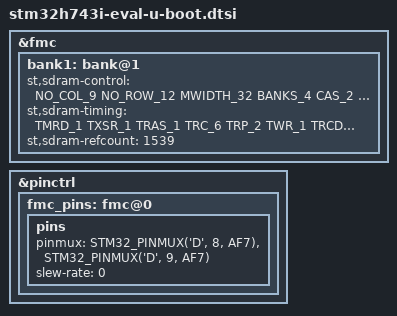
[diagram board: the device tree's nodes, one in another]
// SPDX-License-Identifier: GPL-2.0+

#include <stm32h7-u-boot.dtsi>

&fmc {

	/*
	 * Memory configuration from sdram datasheet IS42S32800G-6BLI
	 * first bank is bank@0
	 * second bank is bank@1
	 */
	bank1: bank@1 {
		st,sdram-control = /bits/ 8 <NO_COL_9
					     NO_ROW_12
					     MWIDTH_32
					     BANKS_4
					     CAS_2
					     SDCLK_3
					     RD_BURST_EN
					     RD_PIPE_DL_0>;
		st,sdram-timing = /bits/ 8 <TMRD_1
					    TXSR_1
					    TRAS_1
					    TRC_6
					    TRP_2
					    TWR_1
					    TRCD_1>;
		st,sdram-refcount = <1539>;
	};
};

&pinctrl {
	fmc_pins: fmc@0 {
		pins {
			pinmux = 
				 <STM32_PINMUX('D', 8, AF7)>,
				 <STM32_PINMUX('D', 9, AF7)>;

			slew-rate = <0>;
		};
	};
};
